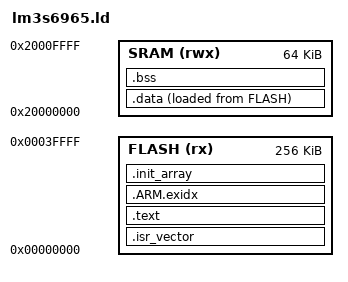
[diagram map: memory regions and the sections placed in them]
/* Minimal linker script for QEMU's lm3s6965evb (Cortex-M3): 256K flash @ 0x0,
   64K SRAM @ 0x20000000. Just enough to run the shared envelope driver under
   semihosting -- this is a differential-test blob, not a real firmware image.
   FIRST DRAFT: to be verified/iterated once the qemu image is available. */
ENTRY(Reset_Handler)

MEMORY {
  FLASH (rx)  : ORIGIN = 0x00000000, LENGTH = 256K
  SRAM  (rwx) : ORIGIN = 0x20000000, LENGTH = 64K
}

_estack = ORIGIN(SRAM) + LENGTH(SRAM);

SECTIONS {
  .isr_vector : { KEEP(*(.isr_vector)) } > FLASH

  .text : {
    *(.text*)
    *(.rodata*)
    . = ALIGN(4);
  } > FLASH

  .ARM.exidx : { *(.ARM.exidx*) } > FLASH

  /* C++ static constructors, iterated by __libc_init_array in startup. */
  .init_array : {
    PROVIDE_HIDDEN(__preinit_array_start = .);
    KEEP(*(.preinit_array*))
    PROVIDE_HIDDEN(__preinit_array_end = .);
    PROVIDE_HIDDEN(__init_array_start = .);
    KEEP(*(SORT(.init_array.*)))
    KEEP(*(.init_array*))
    PROVIDE_HIDDEN(__init_array_end = .);
    PROVIDE_HIDDEN(__fini_array_start = .);
    KEEP(*(.fini_array*))
    PROVIDE_HIDDEN(__fini_array_end = .);
    . = ALIGN(4);
  } > FLASH

  _sidata = LOADADDR(.data);
  .data : {
    . = ALIGN(4);
    _sdata = .;
    *(.data*)
    . = ALIGN(4);
    _edata = .;
  } > SRAM AT> FLASH

  .bss : {
    . = ALIGN(4);
    _sbss = .;
    *(.bss*)
    *(COMMON)
    . = ALIGN(4);
    _ebss = .;
  } > SRAM

  . = ALIGN(8);
  _end = .;   /* newlib _sbrk grows the heap from here */
  end = .;
}
